VERSION "manually crafted"

NS_ :

BS_:

BU_:

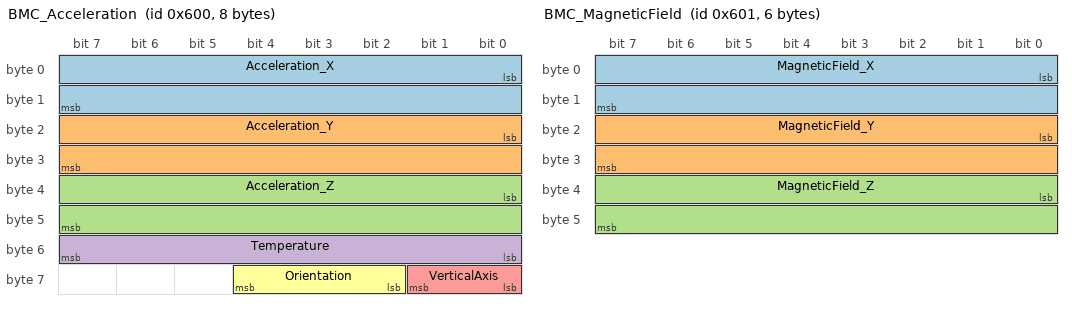
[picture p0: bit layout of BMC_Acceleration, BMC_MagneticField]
BO_ 1536 BMC_Acceleration: 8 Vector__XXX
 SG_ Acceleration_X : 0|16@1- (3.91,0) [-20000|20000] "mG" Vector__XXX
 SG_ Acceleration_Y : 16|16@1- (3.91,0) [-20000|20000] "mG" Vector__XXX
 SG_ Acceleration_Z : 32|16@1- (3.91,0) [-20000|20000] "mG" Vector__XXX
 SG_ Temperature : 48|8@1- (0.5,24) [-40|87.5] "deg C" Vector__XXX
 SG_ VerticalAxis : 56|2@1+ (1,0) [0|3] "" Vector__XXX
 SG_ Orientation : 58|3@1+ (1,0) [0|7] "" Vector__XXX

BO_ 1537 BMC_MagneticField: 6 Vector__XXX
 SG_ MagneticField_X : 0|16@1- (0.3,0) [-9830.4|9830.1] "microT" Vector__XXX
 SG_ MagneticField_Y : 16|16@1- (0.3,0) [-9830.4|9830.1] "microT" Vector__XXX
 SG_ MagneticField_Z : 32|16@1- (0.3,0) [-9830.4|9830.1] "microT" Vector__XXX

BO_ 1552 L3GD20_Rotation_A: 8 Vector__XXX
 SG_ Rotation_X : 0|32@1+ (1,0) [-4000|4000] "deg/s" Vector__XXX
 SG_ Rotation_Y : 32|32@1+ (1,0) [-4000|4000] "deg/s" Vector__XXX

BO_ 1553 L3GD20_Rotation_B: 4 Vector__XXX
 SG_ Rotation_Z : 0|32@1+ (1,0) [-4000|4000] "deg/s" Vector__XXX

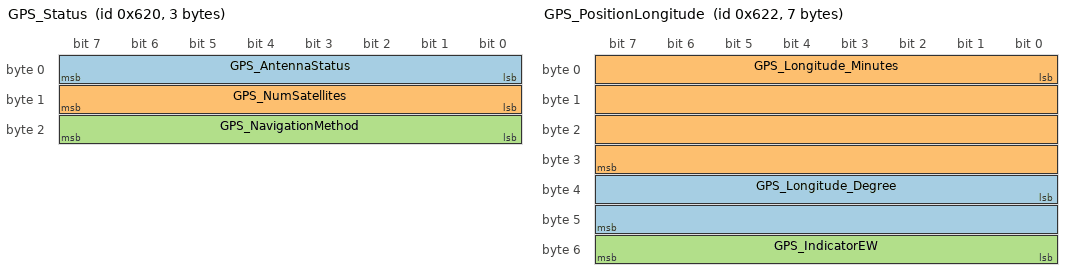
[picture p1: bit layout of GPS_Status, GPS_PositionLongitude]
BO_ 1568 GPS_Status: 3 Vector__XXX
 SG_ GPS_AntennaStatus : 0|8@1+ (1,0) [0|255] "" Vector__XXX
 SG_ GPS_NumSatellites : 8|8@1+ (1,0) [0|255] "" Vector__XXX
 SG_ GPS_NavigationMethod : 16|8@1+ (1,0) [0|255] "" Vector__XXX

BO_ 1569 GPS_CourseSpeed: 8 Vector__XXX
 SG_ GPS_Course : 0|32@1+ (1,0) [0|4294967295] "deg" Vector__XXX
 SG_ GPS_Speed : 32|32@1+ (1,0) [0|4294967295] "km/h" Vector__XXX

BO_ 1570 GPS_PositionLongitude: 7 Vector__XXX
 SG_ GPS_Longitude_Degree : 32|16@1+ (1,0) [0|359] "deg" Vector__XXX
 SG_ GPS_Longitude_Minutes : 0|32@1+ (1,0) [0|4294967295] "" Vector__XXX
 SG_ GPS_IndicatorEW : 48|8@1+ (1,0) [0|255] "" Vector__XXX

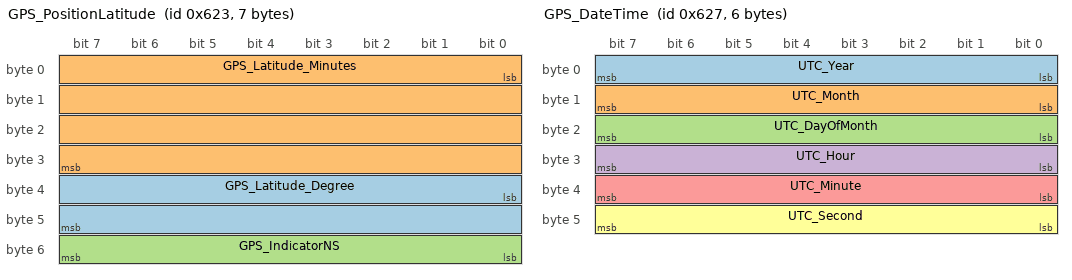
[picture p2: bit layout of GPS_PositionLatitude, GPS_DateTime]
BO_ 1571 GPS_PositionLatitude: 7 Vector__XXX
 SG_ GPS_Latitude_Degree : 32|16@1+ (1,0) [0|359] "deg" Vector__XXX
 SG_ GPS_Latitude_Minutes : 0|32@1+ (1,0) [0|4294967295] "" Vector__XXX
 SG_ GPS_IndicatorNS : 48|8@1+ (1,0) [0|255] "" Vector__XXX

BO_ 1572 GPS_PositionAltitude: 4 Vector__XXX
 SG_ GPS_Altitude : 0|32@1+ (1,0) [0|4294967295] "m" Vector__XXX

BO_ 1573 GPS_Delusions_A: 8 Vector__XXX
 SG_ GPS_PDOP : 0|32@1+ (1,0) [0|4294967295] "" Vector__XXX
 SG_ GPS_HDOP : 32|32@1+ (1,0) [0|4294967295] "" Vector__XXX

BO_ 1574 GPS_Delusions_B: 4 Vector__XXX
 SG_ GPS_VDOP : 0|32@1+ (1,0) [0|4294967295] "" Vector__XXX

BO_ 1575 GPS_DateTime: 6 Vector__XXX
 SG_ UTC_Year : 0|8@1+ (1,0) [0|255] "" Vector__XXX
 SG_ UTC_Month : 8|8@1+ (1,0) [0|255] "" Vector__XXX
 SG_ UTC_DayOfMonth : 16|8@1+ (1,0) [0|255] "" Vector__XXX
 SG_ UTC_Hour : 24|8@1+ (1,0) [0|255] "" Vector__XXX
 SG_ UTC_Minute : 32|8@1+ (1,0) [0|255] "" Vector__XXX
 SG_ UTC_Second : 40|8@1+ (1,0) [0|255] "" Vector__XXX

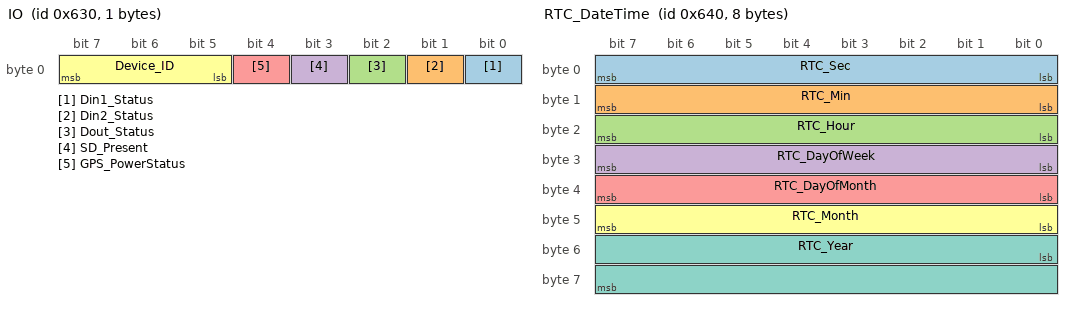
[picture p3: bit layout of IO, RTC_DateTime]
BO_ 1584 IO: 1 Vector__XXX
 SG_ Din1_Status : 0|1@1+ (1,0) [0|1] "" Vector__XXX
 SG_ Din2_Status : 1|1@1+ (1,0) [0|1] "" Vector__XXX
 SG_ Dout_Status : 2|1@1+ (1,0) [0|1] "" Vector__XXX
 SG_ SD_Present : 3|1@1+ (1,0) [0|1] "" Vector__XXX
 SG_ GPS_PowerStatus : 4|1@1+ (1,0) [0|1] "" Vector__XXX
 SG_ Device_ID : 5|3@1+ (1,0) [0|7] "" Vector__XXX

BO_ 1600 RTC_DateTime: 8 Vector__XXX
 SG_ RTC_Sec : 0|8@1+ (1,0) [0|255] "" Vector__XXX
 SG_ RTC_Min : 8|8@1+ (1,0) [0|255] "" Vector__XXX
 SG_ RTC_Hour : 16|8@1+ (1,0) [0|255] "" Vector__XXX
 SG_ RTC_DayOfWeek : 24|8@1+ (1,0) [0|255] "" Vector__XXX
 SG_ RTC_DayOfMonth : 32|8@1+ (1,0) [0|255] "" Vector__XXX
 SG_ RTC_Month : 40|8@1+ (1,0) [0|255] "" Vector__XXX
 SG_ RTC_Year : 48|16@1+ (1,0) [0|65535] "" Vector__XXX

SIG_VALTYPE_ 1552 Rotation_X : 1;
SIG_VALTYPE_ 1552 Rotation_Y : 1;
SIG_VALTYPE_ 1553 Rotation_Z : 1;
SIG_VALTYPE_ 1569 GPS_Course : 1;
SIG_VALTYPE_ 1569 GPS_Speed : 1;
SIG_VALTYPE_ 1570 GPS_Longitude_Minutes : 1;
SIG_VALTYPE_ 1571 GPS_Latitude_Minutes : 1;
SIG_VALTYPE_ 1572 GPS_Altitude : 1;
SIG_VALTYPE_ 1573 GPS_PDOP : 1;
SIG_VALTYPE_ 1573 GPS_HDOP : 1;
SIG_VALTYPE_ 1574 GPS_VDOP : 1;
